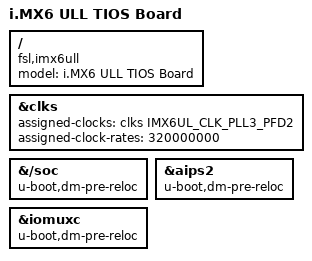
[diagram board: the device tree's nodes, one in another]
/*
 * Copyright 2019 NXP
 *
 * This program is free software; you can redistribute it and/or
 * modify it under the terms of the GNU General Public License
 * as published by the Free Software Foundation; either version 2
 * of the License, or (at your option) any later version.
 */
 
/dts-v1/;

#include "imx6ull.dtsi"
#include "imx6ull-tios-v1.dtsi"

/ {
	model = "i.MX6 ULL TIOS Board";
	compatible = "fsl,imx6ull";
};

&clks {
	assigned-clocks = <&clks IMX6UL_CLK_PLL3_PFD2>;
	assigned-clock-rates = <320000000>;
};

&{/soc} {
	u-boot,dm-pre-reloc;
};

&aips2 {
	u-boot,dm-pre-reloc;
};

&iomuxc {
	u-boot,dm-pre-reloc;
};
